VERSION ""

NS_ :

BS_:

BU_: EON XXX RDC SZL VGSG JBBF RFK FLA RAD1 CAS CID AHM HKL HUD EKP DWA DSC SM_BF GWS VDM DDE1 ACI CCC DSC SM_FA CTM LDM RSE MRSZ VDA EDCK ZBE EGS ACC_Sensor Kombi IHKA ARS ACSM FZD PGS NVC AFS DME FRMFA EMF FKA VSW EPS PDC DKG EHC Diagnosetool_PT_CAN Diagnosetool_K_CAN_System LOC

BO_ 3221225472 VECTOR__INDEPENDENT_SIG_MSG: 0 Vector__XXX
 SG_ AutoWipersOn : 0|1@1+ (1,0) [0|3] ""  XXX
 SG_ Counter_209 : 52|4@1+ (1,0) [0|255] ""  XXX
 SG_ Unknown : 16|16@1- (1,0) [0|65535] ""  XXX
 SG_ YawRate : 0|16@1- (1,0) [0|7] ""  XXX
 SG_ PitchRate : 32|16@1- (1,0) [0|65535] ""  XXX
 SG_ CRC8_209 : 56|8@1+ (1,0) [0|255] ""  XXX
 SG_ Counter_205 : 52|4@1+ (1,0) [0|255] ""  XXX
 SG_ LateralAcceleration : 32|16@1- (1,0) [0|255] ""  XXX
 SG_ YawRate : 0|16@1- (1,0) [0|255] ""  XXX
 SG_ CRC8_205 : 16|16@1- (1,0) [0|65535] ""  XXX
 SG_ AccOn : 23|1@1+ (1,0) [0|255] ""  XXX
 SG_ IgnitionOff : 22|1@1+ (1,0) [0|3] ""  XXX
 SG_ Counter_304 : 32|4@1+ (1,0) [0|15] ""  XXX
 SG_ Checksum_304 : 36|4@1+ (1,0) [0|255] ""  XXX
 SG_ Checksum_184 : 0|8@1+ (1,0) [0|15] ""  XXX
 SG_ Counter_184 : 8|4@1+ (1,0) [0|15] ""  XXX
 SG_ Counter_186 : 48|4@1+ (1,0) [0|14] ""  XXX
 SG_ Checksum_186 : 40|4@1+ (1,0) [0|15] ""  XXX
 SG_ Checksum_191 : 0|8@1+ (1,0) [0|19] ""  XXX
 SG_ Counter_191 : 8|4@1- (1,0) [0|255] ""  XXX
 SG_ TorqueReq : 16|12@1- (0.5,350) [-1024|1023.96875] ""  XXX
 SG_ Counter_464 : 23|8@0+ (1,0) [0|65535] ""  XXX
 SG_ SteeringPosition : 0|16@1- (0.0428316886,0) [-600|600] "degree"  XXX
 SG_ SteeringSpeed : 24|16@1- (0.0428316886,0) [-65535|65535] "degree/s"  XXX
 SG_ Counter_200 : 20|4@1+ (1,0) [0|15] ""  XXX
 SG_ Checksum_946 : 0|8@1+ (1,0) [0|19] ""  XXX
 SG_ Counter_945 : 8|4@1+ (1,0) [0|14] ""  XXX
 SG_ ShiftLeverMode : 32|2@1+ (1,0) [0|3] ""  XXX
 SG_ GearRelated_TBD : 12|4@1+ (1,0) [0|15] ""  XXX
 SG_ Counter_466 : 28|4@1+ (1,0) [0|14] ""  XXX
 SG_ ShiftLeverPosition : 0|4@1+ (1,0) [0|8] ""  XXX
 SG_ xFF : 40|8@1+ (1,0) [0|255] ""  XXX
 SG_ ShiftLeverPositionXOR : 4|4@1+ (1,0) [0|0] "" Vector__XXX
 SG_ SportButtonState : 26|1@1+ (1,0) [0|1] ""  XXX
 SG_ IgnOff : 12|1@0+ (1,0) [0|3] ""  XXX
 SG_ NEW_SIGNAL_1 : 8|8@1+ (1,0) [0|255] ""  XXX
 SG_ NEW_SIGNAL_2 : 0|8@1+ (1,0) [0|15] ""  XXX
 SG_ BatteryVoltage : 7|24@0+ (0.001,0) [0|65535] ""  XXX
 SG_ State2 : 24|4@1+ (1,0) [0|15] ""  XXX
 SG_ State1 : 16|8@1+ (1,0) [0|255] ""  XXX
 SG_ Counter_128 : 28|4@1+ (1,0) [0|15] ""  XXX
 SG_ setMe_0x3FFF : 2|14@1+ (1,0) [0|63] ""  DSC
 SG_ DTC_pressed : 0|1@1+ (1,0) [0|3] ""  DSC
 SG_ State1 : 40|8@1+ (1,0) [0|255] ""  XXX
 SG_ Counter_212 : 52|4@1+ (1,0) [0|255] ""  XXX
 SG_ Checksum_212 : 56|8@1+ (1,0) [0|255] ""  XXX
 SG_ State : 7|8@0+ (1,0) [0|255] ""  XXX
 SG_ ShifterPositionXOR1111 : 16|4@1+ (1,0) [0|15] ""  XXX
 SG_ ParkButtonFirst : 24|2@1+ (1,0) [0|3] ""  XXX
 SG_ Counter_408 : 0|4@1+ (1,0) [0|14] ""  XXX
 SG_ param5 : 32|2@1+ (1,0) [0|3] ""  XXX
 SG_ param1 : 20|2@1+ (1,0) [0|3] ""  XXX
 SG_ m3ShifterPosition : 4|4@1+ (1,0) [0|15] ""  XXX
 SG_ always11 : 38|2@1+ (1,0) [0|3] ""  XXX
 SG_ m3ShifterPositionXOR1111 : 8|4@1+ (1,0) [0|15] ""  XXX
 SG_ param1XOR11 : 22|2@1+ (1,0) [0|3] ""  XXX
 SG_ SideButtonXOR11 : 30|2@1+ (1,0) [0|3] ""  XXX
 SG_ M3_button : 36|2@1+ (1,0) [0|3] ""  XXX
 SG_ SportButtonPressed : 34|2@1+ (1,0) [0|255] ""  XXX
 SG_ SideButton : 28|2@1+ (1,0) [0|3] ""  XXX
 SG_ ParkButtonSecond : 26|2@1+ (1,0) [0|3] ""  XXX
 SG_ SteeringSpeed : 24|16@1- (0.0428316886,0) [0|255] "degree/s"  XXX
 SG_ Counter_201 : 20|4@1+ (1,0) [0|15] ""  DSC
 SG_ SteeringPositionComplementLow : 24|11@1- (1,0) [0|1] ""  DSC
 SG_ SteeringPosition : 0|16@1- (0.0428316886,0) [-600|600] "deg"  DSC
 SG_ NewSignal_0008 : 0|8@1+ (1,0) [0|0] "" Vector__XXX
 SG_ _ : 6|2@1+ (1,0) [0|0] "" Vector__XXX

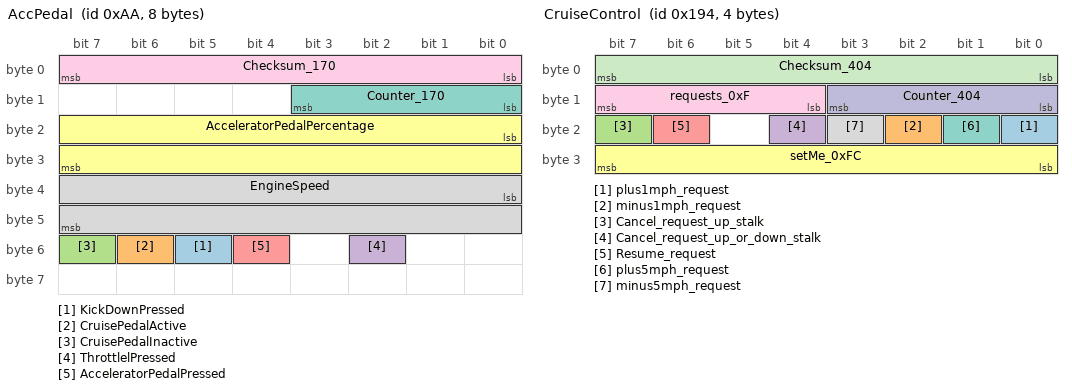
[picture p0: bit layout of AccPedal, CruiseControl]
BO_ 170 AccPedal: 8 DME
 SG_ KickDownPressed : 53|1@0+ (1,0) [0|3] ""  XXX
 SG_ CruisePedalActive : 54|1@0+ (1,0) [0|1] ""  XXX
 SG_ CruisePedalInactive : 55|1@0+ (1,0) [0|1] ""  XXX
 SG_ ThrottlelPressed : 50|1@0+ (1,0) [0|1] ""  XXX
 SG_ AcceleratorPedalPressed : 52|1@0+ (1,0) [0|7] ""  XXX
 SG_ AcceleratorPedalPercentage : 16|16@1+ (0.01,0) [0|100] ""  XXX
 SG_ Counter_170 : 8|4@1+ (1,0) [0|15] ""  XXX
 SG_ EngineSpeed : 32|16@1- (1,0) [0|65535] ""  XXX
 SG_ Checksum_170 : 0|8@1- (1,0) [0|65535] ""  XXX

BO_ 404 CruiseControl: 4 SZL
 SG_ plus1mph_request : 16|1@0+ (1,0) [0|1] ""  XXX
 SG_ minus1mph_request : 18|1@0+ (1,0) [0|1] ""  XXX
 SG_ Cancel_request_up_stalk : 23|1@0+ (1,0) [0|1] ""  XXX
 SG_ Cancel_request_up_or_down_stalk : 20|1@0+ (1,0) [0|1] ""  XXX
 SG_ Resume_request : 22|1@0+ (1,0) [0|1] ""  XXX
 SG_ setMe_0xFC : 31|8@0+ (1,0) [0|255] ""  XXX
 SG_ plus5mph_request : 17|1@0+ (1,0) [0|0] "" Vector__XXX
 SG_ minus5mph_request : 19|1@0+ (1,0) [0|0] "" Vector__XXX
 SG_ requests_0xF : 15|4@0+ (1,0) [0|15] ""  XXX
 SG_ Counter_404 : 11|4@0+ (1,0) [0|15] ""  XXX
 SG_ Checksum_404 : 7|8@0+ (1,0) [0|15] ""  XXX

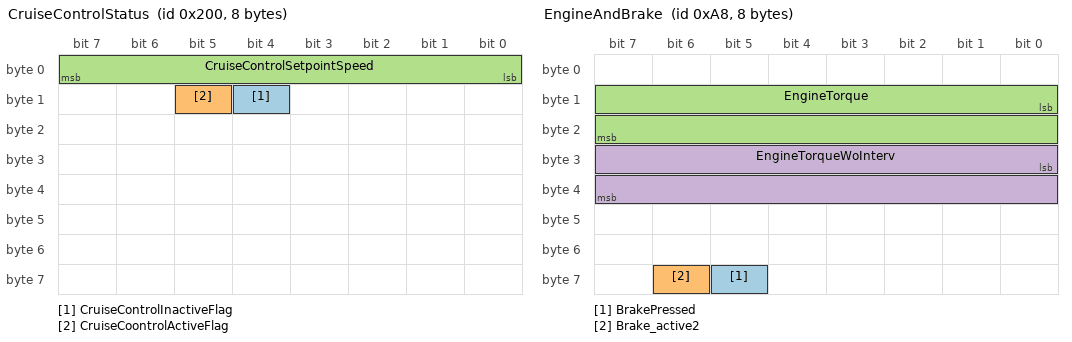
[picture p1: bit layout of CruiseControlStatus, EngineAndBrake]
BO_ 512 CruiseControlStatus: 8 DME
 SG_ CruiseControlInactiveFlag : 12|1@0+ (1,0) [0|1] ""  XXX
 SG_ CruiseCoontrolActiveFlag : 13|1@0+ (1,0) [0|1] ""  XXX
 SG_ CruiseControlSetpointSpeed : 7|8@0+ (0.25,0) [0|255] "mph"  XXX

BO_ 168 EngineAndBrake: 8 DME
 SG_ BrakePressed : 61|1@0+ (1,0) [0|1] ""  XXX
 SG_ Brake_active2 : 62|1@0+ (1,0) [0|1] ""  XXX
 SG_ EngineTorque : 8|16@1- (0.03125,0) [-1024|1023] ""  XXX
 SG_ EngineTorqueWoInterv : 24|16@1- (0.03125,0) [-1024|1023.96875] ""  XXX

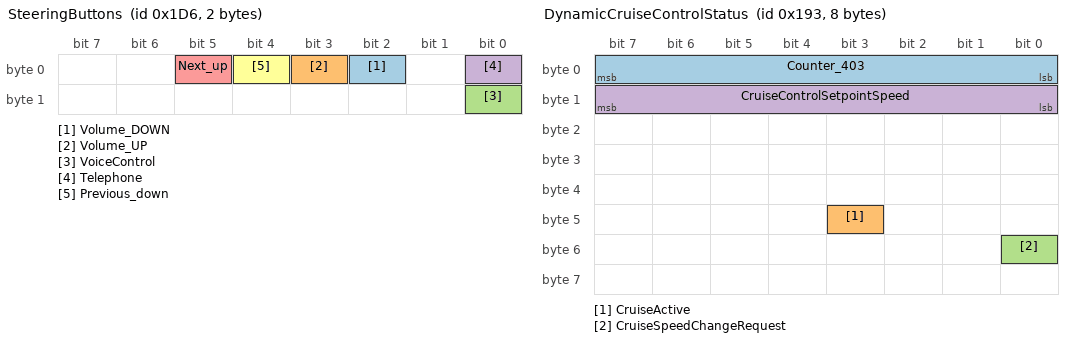
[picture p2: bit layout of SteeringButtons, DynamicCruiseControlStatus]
BO_ 470 SteeringButtons: 2 SZL
 SG_ Volume_DOWN : 2|1@0+ (1,0) [0|1] ""  XXX
 SG_ Volume_UP : 3|1@0+ (1,0) [0|1] ""  XXX
 SG_ VoiceControl : 8|1@0+ (1,0) [0|1] ""  XXX
 SG_ Telephone : 0|1@0+ (1,0) [0|1] ""  XXX
 SG_ Next_up : 5|1@0+ (1,0) [0|1] ""  XXX
 SG_ Previous_down : 4|1@0+ (1,0) [0|1] ""  XXX

BO_ 403 DynamicCruiseControlStatus: 8 DSC
 SG_ Counter_403 : 7|8@0+ (1,0) [0|255] ""  XXX
 SG_ CruiseActive : 43|1@0+ (1,0) [0|1] ""  XXX
 SG_ CruiseSpeedChangeRequest : 48|1@0+ (1,0) [0|1] ""  XXX
 SG_ CruiseControlSetpointSpeed : 15|8@0+ (1,-2) [0|255] "kph/mph"  XXX

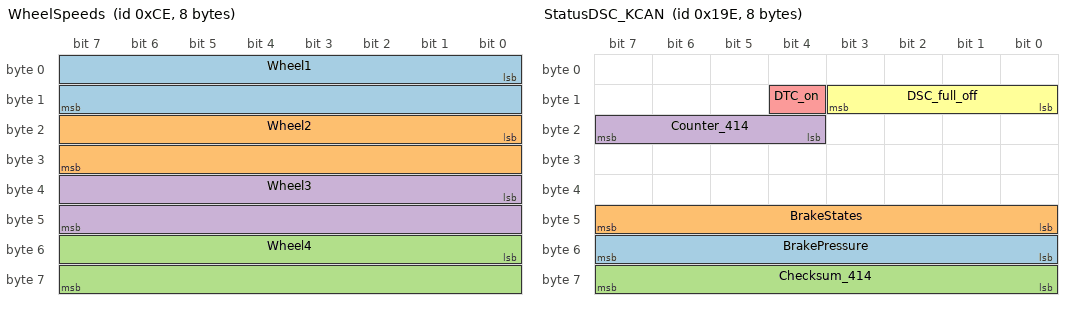
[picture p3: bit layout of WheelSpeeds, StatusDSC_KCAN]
BO_ 206 WheelSpeeds: 8 DSC
 SG_ Wheel1 : 0|16@1- (0.0643699,0) [0|255] "kph"  XXX
 SG_ Wheel2 : 16|16@1- (0.0643699,0) [0|255] "kph"  XXX
 SG_ Wheel4 : 48|16@1- (0.0643699,0) [0|255] "kph"  XXX
 SG_ Wheel3 : 32|16@1- (0.0643699,0) [0|255] "kph"  XXX

BO_ 196 SteeringWheel: 2 DSC
 SG_ SteeringPosition : 0|16@1- (0.0428316886,0) [-600|600] "degree"  XXX

BO_ 414 StatusDSC_KCAN: 8 DSC
 SG_ BrakePressure : 48|8@1- (1,0) [0|255] ""  XXX
 SG_ BrakeStates : 40|8@1+ (1,0) [0|255] ""  XXX
 SG_ Checksum_414 : 56|8@1+ (1,0) [0|15] ""  XXX
 SG_ Counter_414 : 20|4@1+ (1,0) [0|15] ""  XXX
 SG_ DTC_on : 12|1@1+ (1,0) [0|3] ""  XXX
 SG_ DSC_full_off : 8|4@1+ (1,0) [0|15] ""  XXX

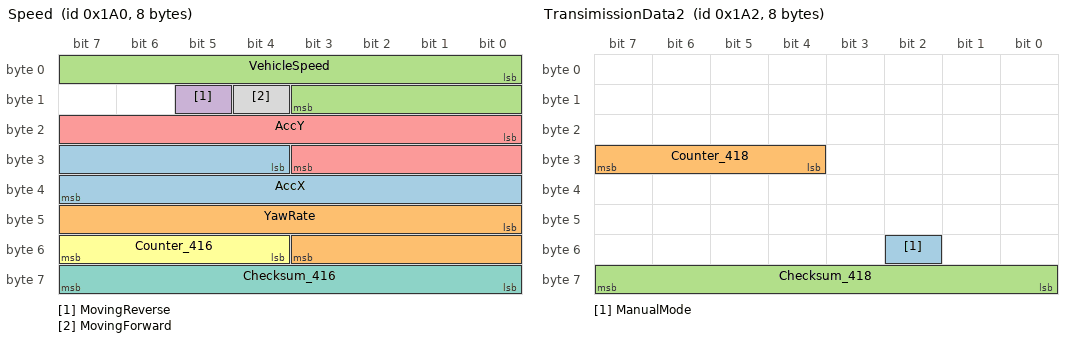
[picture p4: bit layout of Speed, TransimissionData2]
BO_ 416 Speed: 8 DSC
 SG_ AccX : 28|12@1- (1,0) [0|15] ""  XXX
 SG_ YawRate : 40|12@1- (1,0) [0|255] ""  XXX
 SG_ VehicleSpeed : 0|12@1- (0.103,0) [0|255] "kph"  XXX
 SG_ MovingReverse : 13|1@1+ (1,0) [0|3] ""  XXX
 SG_ AccY : 16|12@1- (1,0) [0|255] ""  XXX
 SG_ Counter_416 : 52|4@1+ (1,0) [0|14] ""  XXX
 SG_ Checksum_416 : 56|8@1+ (1,0) [0|15] ""  XXX
 SG_ MovingForward : 12|1@1+ (1,0) [0|15] ""  XXX

BO_ 418 TransimissionData2: 8 EGS
 SG_ ManualMode : 50|1@0+ (1,0) [0|255] ""  XXX
 SG_ Counter_418 : 28|4@1+ (1,0) [0|14] ""  XXX
 SG_ Checksum_418 : 56|8@1+ (1,0) [0|15] ""  XXX

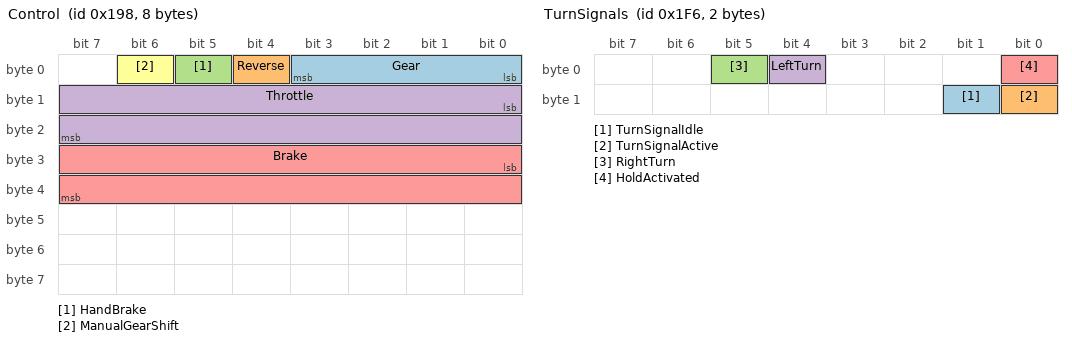
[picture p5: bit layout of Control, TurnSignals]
BO_ 408 Control: 8 GWS
 SG_ Gear : 0|4@1+ (1,0) [0|7] "" Vector__XXX
 SG_ Reverse : 4|1@1+ (1,0) [0|1] "" Vector__XXX
 SG_ HandBrake : 5|1@1+ (1,0) [0|1] "" Vector__XXX
 SG_ Throttle : 8|16@1- (1,0) [0|1] "" Vector__XXX
 SG_ Brake : 24|16@1- (1,0) [0|1] "" Vector__XXX
 SG_ ManualGearShift : 6|1@1+ (1,0) [0|1] "" Vector__XXX

BO_ 422 DistanceRoute: 8 DSC

BO_ 502 TurnSignals: 2 FRMFA
 SG_ TurnSignalIdle : 9|1@0+ (1,0) [0|1] ""  XXX
 SG_ TurnSignalActive : 8|1@0+ (1,0) [0|1] ""  XXX
 SG_ RightTurn : 5|1@0+ (1,0) [0|1] ""  XXX
 SG_ LeftTurn : 4|1@1+ (1,0) [0|1] ""  XXX
 SG_ HoldActivated : 0|1@1+ (1,0) [0|1] ""  XXX

BO_ 428 Status_ARS_module: 8 ARS

BO_ 510 Crash: 8 ACSM

BO_ 714 Outside_temperature: 8 Kombi

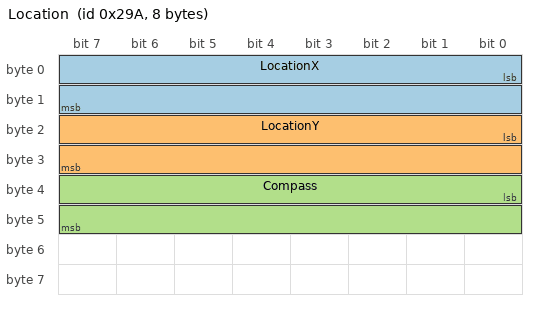
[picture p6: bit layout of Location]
BO_ 666 Location: 8 LOC
 SG_ LocationX : 0|16@1- (1,0) [-16384|16384] "" Vector__XXX
 SG_ LocationY : 16|16@1- (1,0) [-16384|16384] "" Vector__XXX
 SG_ Compass : 32|16@1- (1,0) [0|360] "" Vector__XXX

CM_ SG_ 3221225472 ShiftLeverMode "On the dashboard, there are displayed:  D1...D7 in Normal. S1...S6 in Sport.  M1..M7 in Manual";
CM_ SG_ 3221225472 setMe_0x3FFF "All ones";
CM_ SG_ 3221225472 DTC_pressed "Traction control off. Message transmitted when pressed. Few presses may be required followed by off.";
CM_ SG_ 3221225472 ParkButtonFirst "0x1 = pressed";
CM_ SG_ 3221225472 param5 "Always 0 in 135i.";
CM_ SG_ 3221225472 param1 "can not be 0x03. Always 0 in 135i.";
CM_ SG_ 3221225472 SideButtonXOR11 "Complement value";
CM_ SG_ 3221225472 M3_button "M3 POWER (?)";
CM_ SG_ 3221225472 SportButtonPressed "0x1 = pressed;";
CM_ SG_ 3221225472 SideButton "0x1 = pressed;";
CM_ SG_ 3221225472 ParkButtonSecond "Redundant buton. 0x1 = pressed;";
CM_ SG_ 170 ThrottlelPressed "Active when accelerator pedal pressed or cruise control: drives";
CM_ SG_ 170 AcceleratorPedalPressed "Active only when driver actually presses the pedal";
CM_ SG_ 170 AcceleratorPedalPercentage "ToDo Factor to be adjusted";
CM_ SG_ 170 EngineSpeed "It's hard to say that is even a rate";
CM_ SG_ 404 plus1mph_request "Appears when +1mph/kph stalk is depressed";
CM_ SG_ 404 minus1mph_request "Appears when -1mph/kph stalk is depressed";
CM_ SG_ 404 Cancel_request_up_stalk "Appears when cancel stalk (up) is depressed";
CM_ SG_ 404 Cancel_request_up_or_down_stalk "Appears when cancel stalk (up or down) is depressed";
CM_ SG_ 404 Resume_request "It appears when resume stalk button is depressed";
CM_ SG_ 404 Counter_404 "Message is sent at higher rate when cruise stalk is pressed";
CM_ SG_ 168 BrakePressed "Brake when driver presses the brake or hill hold";
CM_ SG_ 168 EngineTorque "Engine torque without inertia - combustion torque";
CM_ SG_ 168 EngineTorqueWoInterv "Engine torque without inertia and without shift intervention";
CM_ SG_ 403 CruiseControlSetpointSpeed "Speed target - unit depends on locale";
CM_ SG_ 414 DSC_full_off "0x4 enabling, 0xA enabled. TBD";
CM_ SG_ 416 YawRate "Lateral Acceleration";
CM_ SG_ 502 TurnSignalIdle "Turn signal off";
CM_ SG_ 502 TurnSignalActive "Turn signal on or transitioning";
CM_ SG_ 502 RightTurn "Indicates right blinker or when steering returning right clears left blinker";
CM_ SG_ 502 LeftTurn "Indicates left blinker or when steering returning left clears right blinker";
CM_ SG_ 502 HoldActivated "Spikes down if blinker cleared with timeout or turn. Stays off if blinker cleared with stalk";
SIG_VALTYPE_ 408 Throttle : 1;
SIG_VALTYPE_ 408 Brake : 1;
SIG_VALTYPE_ 666 Compass : 1;
